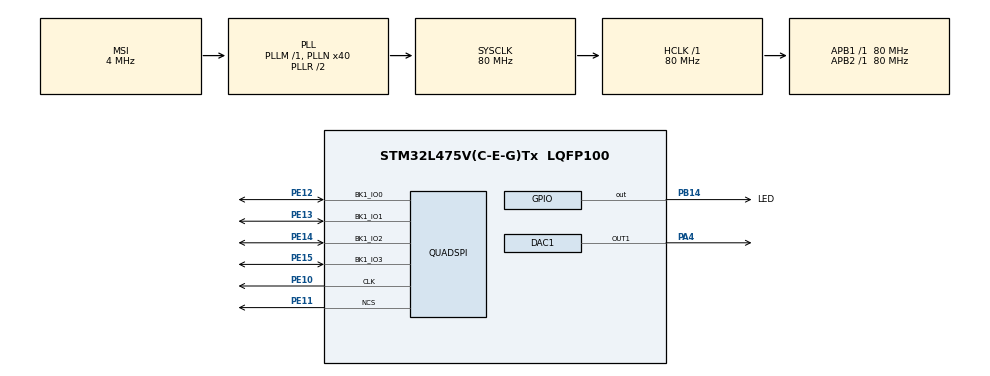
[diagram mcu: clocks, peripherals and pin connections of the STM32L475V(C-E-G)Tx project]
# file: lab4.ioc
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Mcu.Family=STM32L4
RCC.MSI_VALUE=4000000
Dma.DAC_CH1.0.Mode=DMA_CIRCULAR
Dma.DAC_CH1.0.MemDataAlignment=DMA_MDATAALIGN_BYTE
RCC.CortexFreq_Value=80000000
PB14.GPIO_Label=LED
PE10.Mode=Single Bank
RCC.SYSCLKSource=RCC_SYSCLKSOURCE_PLLCLK
ProjectManager.StackSize=0x400
PB3\ (JTDO-TRACESWO).Signal=SYS_JTDO-SWO
NVIC.DMA1_Channel3_IRQn=true\:0\:0\:false\:false\:true\:false\:true
Dma.DAC_CH1.0.Direction=DMA_MEMORY_TO_PERIPH
PE11.Mode=Single Bank
Dma.DAC_CH1.0.Instance=DMA1_Channel3
ProjectManager.TargetToolchain=STM32CubeIDE
SH.COMP_DAC11_group.0=DAC1_OUT1,DAC_OUT1
RCC.HCLKFreq_Value=80000000
RCC.APB2TimFreq_Value=80000000
Dma.DAC_CH1.0.MemInc=DMA_MINC_ENABLE
RCC.USBFreq_Value=48000000
PE11.Signal=QUADSPI_NCS
RCC.LSE_VALUE=32768
RCC.AHBFreq_Value=80000000
PB14.Signal=GPIO_Output
RCC.HSE_VALUE=8000000
board=B-L475E-IOT01A1
RCC.VCOOutputFreq_Value=160000000
RCC.APB2Freq_Value=80000000
PE14.Signal=QUADSPI_BK1_IO2
PE13.Signal=QUADSPI_BK1_IO1
PE15.Signal=QUADSPI_BK1_IO3
VP_TIM2_VS_ClockSourceINT.Mode=Internal
PE14.Mode=Single Bank
NVIC.TIM2_IRQn=true\:0\:0\:false\:false\:true\:true\:true
RCC.ADCFreq_Value=48000000
Dma.DAC_CH1.0.PeriphDataAlignment=DMA_PDATAALIGN_BYTE
PE13.Mode=Single Bank
DAC1.DAC_Trigger-DAC_OUT1=DAC_TRIGGER_T2_TRGO
TIM2.Period=834
PE10.Signal=QUADSPI_CLK
Mcu.Name=STM32L475V(C-E-G)Tx
PE12.Signal=QUADSPI_BK1_IO0
Dma.DAC_CH1.0.PeriphInc=DMA_PINC_DISABLE
PA4.Signal=COMP_DAC11_group
RCC.SYSCLKFreq_VALUE=80000000
Mcu.Package=LQFP100
ProjectManager.HeapSize=0x200
Dma.DAC_CH1.0.Priority=DMA_PRIORITY_LOW
RCC.HSI_VALUE=16000000
NVIC.PriorityGroup=NVIC_PRIORITYGROUP_4
TIM2.TIM_MasterOutputTrigger=TIM_TRGO_UPDATE
RCC.PLLN=40
RCC.APB1TimFreq_Value=80000000
PA13\ (JTMS-SWDIO).Signal=SYS_JTMS-SWDIO
Dma.Request0=DAC_CH1
RCC.APB1Freq_Value=80000000
PE15.Mode=Single Bank
RCC.PLLSAI1N=24
PE12.Mode=Single Bank

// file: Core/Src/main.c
/* USER CODE BEGIN Header */
/**
  ******************************************************************************
  * @file           : main.c
  * @brief          : Main program body
  ******************************************************************************
  * @attention
  *
  * <h2><center>&copy; Copyright (c) 2020 STMicroelectronics.
  * All rights reserved.</center></h2>
  *
  * This software component is licensed by ST under BSD 3-Clause license,
  * the "License"; You may not use this file except in compliance with the
  * License. You may obtain a copy of the License at:
  *                        opensource.org/licenses/BSD-3-Clause
  *
  ******************************************************************************
  */
/* USER CODE END Header */
#include "main.h"

/* USER CODE BEGIN Includes */
#include "arm_math.h"
#include <math.h>
/* USER CODE END Includes */

DAC_HandleTypeDef hdac1;
DMA_HandleTypeDef hdma_dac_ch1;

TIM_HandleTypeDef htim2;

/* USER CODE BEGIN PV */
uint8_t sineValues1[64];
uint8_t sineValues2[32];
uint8_t sineValues3[128];
uint8_t nextDACValue = 0;
uint8_t currentSineWave = 1;
/* USER CODE END PV */

void SystemClock_Config(void);
static void MX_GPIO_Init(void);
static void MX_DMA_Init(void);
static void MX_DAC1_Init(void);
static void MX_TIM2_Init(void);
/* USER CODE BEGIN PFP */
void HAL_GPIO_EXTI_Callback(uint16_t GPIO_Pin);
void HAL_TIM_PeriodElapsedCallback(TIM_HandleTypeDef* htim);
/* USER CODE END PFP */

int main(void)
{

  /* MCU Configuration--------------------------------------------------------*/

  /* Reset of all peripherals, Initializes the Flash interface and the Systick. */
  HAL_Init();

  /* Configure the system clock */
  SystemClock_Config();

  /* Initialize all configured peripherals */
  MX_GPIO_Init();
  MX_DMA_Init();
  MX_DAC1_Init();
  MX_TIM2_Init();
  /* USER CODE BEGIN 2 */
  float radian1 = 0;
  float radian2 = 0;
  float radian3 = 0;
  for (int i = 0; i < 64; i++) {
	  sineValues1[i] = (100 * arm_sin_f32(radian1)) + 100;
	  radian1 += M_PI_4 / 8;
  }
  for (int i = 0; i < 32; i++) {
	  sineValues2[i] = (100 * arm_sin_f32(radian2)) + 100;
	  radian2 += M_PI_4 / 4;
  }
  for (int i = 0; i < 128; i++) {
	  sineValues3[i] = (100 * arm_sin_f32(radian3)) + 100;
	  radian3 += M_PI_4 / 16;
  }
  HAL_TIM_Base_Start(&htim2);
  HAL_DAC_Start_DMA(&hdac1, DAC_CHANNEL_1, (uint32_t*) sineValues1, 64, DAC_ALIGN_8B_R);
//  HAL_TIM_Base_Start_IT(&htim2);
  /* USER CODE END 2 */

  /* Infinite loop */
  while (1)
  {

  }
}

void SystemClock_Config(void)
{
  RCC_OscInitTypeDef RCC_OscInitStruct = {0};
  RCC_ClkInitTypeDef RCC_ClkInitStruct = {0};

  /** Initializes the RCC Oscillators according to the specified parameters
  * in the RCC_OscInitTypeDef structure.
  */
  RCC_OscInitStruct.OscillatorType = RCC_OSCILLATORTYPE_MSI;
  RCC_OscInitStruct.MSIState = RCC_MSI_ON;
  RCC_OscInitStruct.MSICalibrationValue = 0;
  RCC_OscInitStruct.MSIClockRange = RCC_MSIRANGE_6;
  RCC_OscInitStruct.PLL.PLLState = RCC_PLL_ON;
  RCC_OscInitStruct.PLL.PLLSource = RCC_PLLSOURCE_MSI;
  RCC_OscInitStruct.PLL.PLLM = 1;
  RCC_OscInitStruct.PLL.PLLN = 40;
  RCC_OscInitStruct.PLL.PLLP = RCC_PLLP_DIV7;
  RCC_OscInitStruct.PLL.PLLQ = RCC_PLLQ_DIV2;
  RCC_OscInitStruct.PLL.PLLR = RCC_PLLR_DIV2;
  if (HAL_RCC_OscConfig(&RCC_OscInitStruct) != HAL_OK)
  {
    Error_Handler();
  }
  /** Initializes the CPU, AHB and APB buses clocks
  */
  RCC_ClkInitStruct.ClockType = RCC_CLOCKTYPE_HCLK|RCC_CLOCKTYPE_SYSCLK
                              |RCC_CLOCKTYPE_PCLK1|RCC_CLOCKTYPE_PCLK2;
  RCC_ClkInitStruct.SYSCLKSource = RCC_SYSCLKSOURCE_PLLCLK;
  RCC_ClkInitStruct.AHBCLKDivider = RCC_SYSCLK_DIV1;
  RCC_ClkInitStruct.APB1CLKDivider = RCC_HCLK_DIV1;
  RCC_ClkInitStruct.APB2CLKDivider = RCC_HCLK_DIV1;

  if (HAL_RCC_ClockConfig(&RCC_ClkInitStruct, FLASH_LATENCY_4) != HAL_OK)
  {
    Error_Handler();
  }
  /** Configure the main internal regulator output voltage
  */
  if (HAL_PWREx_ControlVoltageScaling(PWR_REGULATOR_VOLTAGE_SCALE1) != HAL_OK)
  {
    Error_Handler();
  }
}

static void MX_DAC1_Init(void)
{

  DAC_ChannelConfTypeDef sConfig = {0};

  /** DAC Initialization
  */
  hdac1.Instance = DAC1;
  if (HAL_DAC_Init(&hdac1) != HAL_OK)
  {
    Error_Handler();
  }
  /** DAC channel OUT1 config
  */
  sConfig.DAC_SampleAndHold = DAC_SAMPLEANDHOLD_DISABLE;
  sConfig.DAC_Trigger = DAC_TRIGGER_T2_TRGO;
  sConfig.DAC_OutputBuffer = DAC_OUTPUTBUFFER_ENABLE;
  sConfig.DAC_ConnectOnChipPeripheral = DAC_CHIPCONNECT_DISABLE;
  sConfig.DAC_UserTrimming = DAC_TRIMMING_FACTORY;
  if (HAL_DAC_ConfigChannel(&hdac1, &sConfig, DAC_CHANNEL_1) != HAL_OK)
  {
    Error_Handler();
  }

}

static void MX_TIM2_Init(void)
{

  TIM_ClockConfigTypeDef sClockSourceConfig = {0};
  TIM_MasterConfigTypeDef sMasterConfig = {0};

  htim2.Instance = TIM2;
  htim2.Init.Prescaler = 0;
  htim2.Init.CounterMode = TIM_COUNTERMODE_UP;
  htim2.Init.Period = 834;
  htim2.Init.ClockDivision = TIM_CLOCKDIVISION_DIV1;
  htim2.Init.AutoReloadPreload = TIM_AUTORELOAD_PRELOAD_DISABLE;
  if (HAL_TIM_Base_Init(&htim2) != HAL_OK)
  {
    Error_Handler();
  }
  sClockSourceConfig.ClockSource = TIM_CLOCKSOURCE_INTERNAL;
  if (HAL_TIM_ConfigClockSource(&htim2, &sClockSourceConfig) != HAL_OK)
  {
    Error_Handler();
  }
  sMasterConfig.MasterOutputTrigger = TIM_TRGO_UPDATE;
  sMasterConfig.MasterSlaveMode = TIM_MASTERSLAVEMODE_DISABLE;
  if (HAL_TIMEx_MasterConfigSynchronization(&htim2, &sMasterConfig) != HAL_OK)
  {
    Error_Handler();
  }

}

static void MX_DMA_Init(void)
{

  /* DMA controller clock enable */
  __HAL_RCC_DMA1_CLK_ENABLE();

  /* DMA interrupt init */
  /* DMA1_Channel3_IRQn interrupt configuration */
  HAL_NVIC_SetPriority(DMA1_Channel3_IRQn, 0, 0);
  HAL_NVIC_EnableIRQ(DMA1_Channel3_IRQn);

}

static void MX_GPIO_Init(void)
{
  GPIO_InitTypeDef GPIO_InitStruct = {0};

  /* GPIO Ports Clock Enable */
  __HAL_RCC_GPIOC_CLK_ENABLE();
  __HAL_RCC_GPIOA_CLK_ENABLE();
  __HAL_RCC_GPIOB_CLK_ENABLE();

  /*Configure GPIO pin Output Level */
  HAL_GPIO_WritePin(LED_GPIO_Port, LED_Pin, GPIO_PIN_RESET);

  /*Configure GPIO pin : BUTTON_Pin */
  GPIO_InitStruct.Pin = BUTTON_Pin;
  GPIO_InitStruct.Mode = GPIO_MODE_IT_RISING_FALLING;
  GPIO_InitStruct.Pull = GPIO_NOPULL;
  HAL_GPIO_Init(BUTTON_GPIO_Port, &GPIO_InitStruct);

  /*Configure GPIO pin : LED_Pin */
  GPIO_InitStruct.Pin = LED_Pin;
  GPIO_InitStruct.Mode = GPIO_MODE_OUTPUT_PP;
  GPIO_InitStruct.Pull = GPIO_NOPULL;
  GPIO_InitStruct.Speed = GPIO_SPEED_FREQ_LOW;
  HAL_GPIO_Init(LED_GPIO_Port, &GPIO_InitStruct);

  /* EXTI interrupt init*/
  HAL_NVIC_SetPriority(EXTI15_10_IRQn, 0, 0);
  HAL_NVIC_EnableIRQ(EXTI15_10_IRQn);

}

/* USER CODE BEGIN 4 */
void HAL_GPIO_EXTI_Callback(uint16_t GPIO_Pin) {
	if (GPIO_Pin == BUTTON_Pin) {
		HAL_GPIO_TogglePin(LED_GPIO_Port, LED_Pin);
		HAL_DAC_Stop_DMA(&hdac1, DAC_CHANNEL_1);
		currentSineWave += 1;
		if (currentSineWave > 3) {
			currentSineWave = 1;
			HAL_DAC_Start_DMA(&hdac1, DAC_CHANNEL_1, (uint32_t*) sineValues1, 64, DAC_ALIGN_8B_R);
		} else if (currentSineWave == 2) {
			HAL_DAC_Start_DMA(&hdac1, DAC_CHANNEL_1, (uint32_t*) sineValues2, 32, DAC_ALIGN_8B_R);
		} else if (currentSineWave == 3) {
			HAL_DAC_Start_DMA(&hdac1, DAC_CHANNEL_1, (uint32_t*) sineValues3, 128, DAC_ALIGN_8B_R);
		}
	}
}

//void HAL_TIM_PeriodElapsedCallback(TIM_HandleTypeDef* htim) {
//	if (htim->Instance == htim2.Instance) {
//		uint8_t DAC_Value = sineValues[nextDACValue];
//		nextDACValue += 1;
//		if (nextDACValue >= 64) {
//			nextDACValue = 0;
//		}
//		HAL_DAC_SetValue(&hdac1, DAC_CHANNEL_1, DAC_ALIGN_8B_R, DAC_Value);
//	}
//}
/* USER CODE END 4 */

void Error_Handler(void)
{
}

/************************ (C) COPYRIGHT STMicroelectronics *****END OF FILE****/
